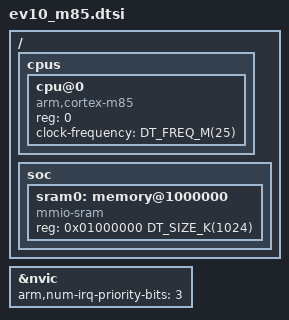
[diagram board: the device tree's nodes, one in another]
/*
 * Copyright (c) 2024-2025 Renesas Electronics Corporation
 *
 * SPDX-License-Identifier: Apache-2.0
 */

#include <mem.h>
#include <arm/armv8.1-m.dtsi>
#include <freq.h>

/ {
	cpus {
		#address-cells = <1>;
		#size-cells = <0>;

		cpu@0 {
			device_type = "cpu";
			compatible = "arm,cortex-m85";
			reg = <0>;
			clock-frequency = <DT_FREQ_M(25)>;
			#address-cells = <1>;
			#size-cells = <1>;

			/*
			mpu: mpu@e000ed90 {
				compatible = "arm,armv8.1m-mpu";
				reg = <0xe000ed90 0x40>;
			};
			*/
		};

	};

	soc {

		sram0: memory@1000000 {
			compatible = "mmio-sram";
			reg = <0x01000000 DT_SIZE_K(1024)>;
		};

	};
};

&nvic {
	arm,num-irq-priority-bits = <3>;
};
